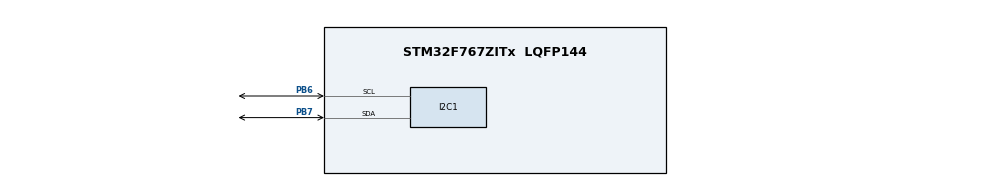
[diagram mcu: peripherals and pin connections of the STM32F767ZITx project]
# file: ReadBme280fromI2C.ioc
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CORTEX_M7.default_mode_Activation=1
Mcu.Family=STM32F7
Mcu.Name=STM32F767ZITx
Mcu.Package=LQFP144
NVIC.PriorityGroup=NVIC_PRIORITYGROUP_4
PB6.Mode=I2C
PB6.Signal=I2C1_SCL
PB7.Mode=I2C
PB7.Signal=I2C1_SDA
ProjectManager.HeapSize=0x200
ProjectManager.StackSize=0x400
ProjectManager.TargetToolchain=STM32CubeIDE
RCC.HSE_VALUE=25000000
RCC.HSI_VALUE=16000000
RCC.LSE_VALUE=32768
RCC.USBFreq_Value=96000000
RCC.VCOOutputFreq_Value=192000000
board=custom

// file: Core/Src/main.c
/* USER CODE BEGIN Header */
/**
  ******************************************************************************
  * @file           : main.c
  * @brief          : Main program body
  ******************************************************************************
  * @attention
  *
  * Copyright (c) 2025 STMicroelectronics.
  * All rights reserved.
  *
  * This software is licensed under terms that can be found in the LICENSE file
  * in the root directory of this software component.
  * If no LICENSE file comes with this software, it is provided AS-IS.
  *
  ******************************************************************************
  */
/* USER CODE END Header */
#include "main.h"

I2C_HandleTypeDef hi2c1;

// Use 7-bit address + 1-bit for read/write bit.
// We need to shift the 8-bit value over by 1 bit left.
// to leave room for the final read/write bit.
#define BME280_ADDR 0x76 << 1
double temperature;

void SystemClock_Config(void);
static void MPU_Config(void);
static void MX_GPIO_Init(void);
static void MX_I2C1_Init(void);

/* USER CODE BEGIN 0 */

void BME280_Init(void) {
    uint8_t config[2];
    config[0] = 0xF4;  // ctrl_meas register
    config[1] = 0x27;  // Set oversampling to 0x27
    HAL_I2C_Mem_Write(&hi2c1, BME280_ADDR, config[0], I2C_MEMADD_SIZE_8BIT, &config[1], 1, 100);
}

void BME280_ReadCalibrationData(uint16_t* dig_T1, int16_t* dig_T2, int16_t* dig_T3) {
    uint8_t calib[6];
    HAL_I2C_Mem_Read(&hi2c1, BME280_ADDR, 0x88, I2C_MEMADD_SIZE_8BIT, calib, 6, 100);
    *dig_T1 = (uint16_t)((calib[1] << 8) | calib[0]);
    *dig_T2 = (int16_t)((calib[3] << 8) | calib[2]);
    *dig_T3 = (int16_t)((calib[5] << 8) | calib[4]);
}

int32_t BME280_ReadRawTemperature(void) {
    uint8_t data[3];
    HAL_I2C_Mem_Read(&hi2c1, BME280_ADDR, 0xFA, I2C_MEMADD_SIZE_8BIT, data, 3, 100);
    return (int32_t)(((data[0] << 16) | (data[1] << 8) | data[2]) >> 4);
}

double BME280_CompensateTemperature(int32_t adc_T, uint16_t dig_T1, int16_t dig_T2, int16_t dig_T3) {
    double var1, var2, T;
    var1 = (((double)adc_T) / 16384.0 - ((double)dig_T1) / 1024.0) * ((double)dig_T2);
    var2 = ((((double)adc_T) / 131072.0 - ((double)dig_T1) / 8192.0) * (((double)adc_T) / 131072.0 - ((double)dig_T1) / 8192.0)) * ((double)dig_T3);
    T = (var1 + var2) / 5120.0;
    return T;
}

/* USER CODE END 0 */

int main(void)
{

  /* MPU Configuration--------------------------------------------------------*/
  MPU_Config();

  /* MCU Configuration--------------------------------------------------------*/

  /* Reset of all peripherals, Initializes the Flash interface and the Systick. */
  HAL_Init();

  /* Configure the system clock */
  SystemClock_Config();

  /* Initialize all configured peripherals */
  MX_GPIO_Init();
  MX_I2C1_Init();
  /* USER CODE BEGIN 2 */
  // Initialize all configured peripherals (e.g., I2C)
  // Initialize BME280 sensor
   BME280_Init();

   // Calibration data variables
   uint16_t dig_T1;
   int16_t dig_T2, dig_T3;

   // Read calibration data
   BME280_ReadCalibrationData(&dig_T1, &dig_T2, &dig_T3);
  /* USER CODE END 2 */

  /* Infinite loop */
  /* USER CODE BEGIN WHILE */
  while (1)
  {
	  // Read raw temperature data
	         int32_t rawTemp = BME280_ReadRawTemperature();

	         // Compensate the raw temperature data using calibration data
	         temperature = BME280_CompensateTemperature(rawTemp, dig_T1, dig_T2, dig_T3);

	         // Delay for a while (e.g., 1 second)
	         HAL_Delay(1000);

    /* USER CODE END WHILE */

  }
}

void SystemClock_Config(void)
{
  RCC_OscInitTypeDef RCC_OscInitStruct = {0};
  RCC_ClkInitTypeDef RCC_ClkInitStruct = {0};

  /** Configure the main internal regulator output voltage
  */
  __HAL_RCC_PWR_CLK_ENABLE();
  __HAL_PWR_VOLTAGESCALING_CONFIG(PWR_REGULATOR_VOLTAGE_SCALE3);

  /** Initializes the RCC Oscillators according to the specified parameters
  * in the RCC_OscInitTypeDef structure.
  */
  RCC_OscInitStruct.OscillatorType = RCC_OSCILLATORTYPE_HSI;
  RCC_OscInitStruct.HSIState = RCC_HSI_ON;
  RCC_OscInitStruct.HSICalibrationValue = RCC_HSICALIBRATION_DEFAULT;
  RCC_OscInitStruct.PLL.PLLState = RCC_PLL_NONE;
  if (HAL_RCC_OscConfig(&RCC_OscInitStruct) != HAL_OK)
  {
    Error_Handler();
  }

  /** Initializes the CPU, AHB and APB buses clocks
  */
  RCC_ClkInitStruct.ClockType = RCC_CLOCKTYPE_HCLK|RCC_CLOCKTYPE_SYSCLK
                              |RCC_CLOCKTYPE_PCLK1|RCC_CLOCKTYPE_PCLK2;
  RCC_ClkInitStruct.SYSCLKSource = RCC_SYSCLKSOURCE_HSI;
  RCC_ClkInitStruct.AHBCLKDivider = RCC_SYSCLK_DIV1;
  RCC_ClkInitStruct.APB1CLKDivider = RCC_HCLK_DIV1;
  RCC_ClkInitStruct.APB2CLKDivider = RCC_HCLK_DIV1;

  if (HAL_RCC_ClockConfig(&RCC_ClkInitStruct, FLASH_LATENCY_0) != HAL_OK)
  {
    Error_Handler();
  }
}

static void MX_I2C1_Init(void)
{

  hi2c1.Instance = I2C1;
  hi2c1.Init.Timing = 0x00303D5B;
  hi2c1.Init.OwnAddress1 = 0;
  hi2c1.Init.AddressingMode = I2C_ADDRESSINGMODE_7BIT;
  hi2c1.Init.DualAddressMode = I2C_DUALADDRESS_DISABLE;
  hi2c1.Init.OwnAddress2 = 0;
  hi2c1.Init.OwnAddress2Masks = I2C_OA2_NOMASK;
  hi2c1.Init.GeneralCallMode = I2C_GENERALCALL_DISABLE;
  hi2c1.Init.NoStretchMode = I2C_NOSTRETCH_DISABLE;
  if (HAL_I2C_Init(&hi2c1) != HAL_OK)
  {
    Error_Handler();
  }

  /** Configure Analogue filter
  */
  if (HAL_I2CEx_ConfigAnalogFilter(&hi2c1, I2C_ANALOGFILTER_ENABLE) != HAL_OK)
  {
    Error_Handler();
  }

  /** Configure Digital filter
  */
  if (HAL_I2CEx_ConfigDigitalFilter(&hi2c1, 0) != HAL_OK)
  {
    Error_Handler();
  }

}

static void MX_GPIO_Init(void)
{

  /* GPIO Ports Clock Enable */
  __HAL_RCC_GPIOB_CLK_ENABLE();

}

 /* MPU Configuration */

void MPU_Config(void)
{
  MPU_Region_InitTypeDef MPU_InitStruct = {0};

  /* Disables the MPU */
  HAL_MPU_Disable();

  /** Initializes and configures the Region and the memory to be protected
  */
  MPU_InitStruct.Enable = MPU_REGION_ENABLE;
  MPU_InitStruct.Number = MPU_REGION_NUMBER0;
  MPU_InitStruct.BaseAddress = 0x0;
  MPU_InitStruct.Size = MPU_REGION_SIZE_4GB;
  MPU_InitStruct.SubRegionDisable = 0x87;
  MPU_InitStruct.TypeExtField = MPU_TEX_LEVEL0;
  MPU_InitStruct.AccessPermission = MPU_REGION_NO_ACCESS;
  MPU_InitStruct.DisableExec = MPU_INSTRUCTION_ACCESS_DISABLE;
  MPU_InitStruct.IsShareable = MPU_ACCESS_SHAREABLE;
  MPU_InitStruct.IsCacheable = MPU_ACCESS_NOT_CACHEABLE;
  MPU_InitStruct.IsBufferable = MPU_ACCESS_NOT_BUFFERABLE;

  HAL_MPU_ConfigRegion(&MPU_InitStruct);
  /* Enables the MPU */
  HAL_MPU_Enable(MPU_PRIVILEGED_DEFAULT);

}

void Error_Handler(void)
{
  __disable_irq();
  while (1)
  {
  }
}
